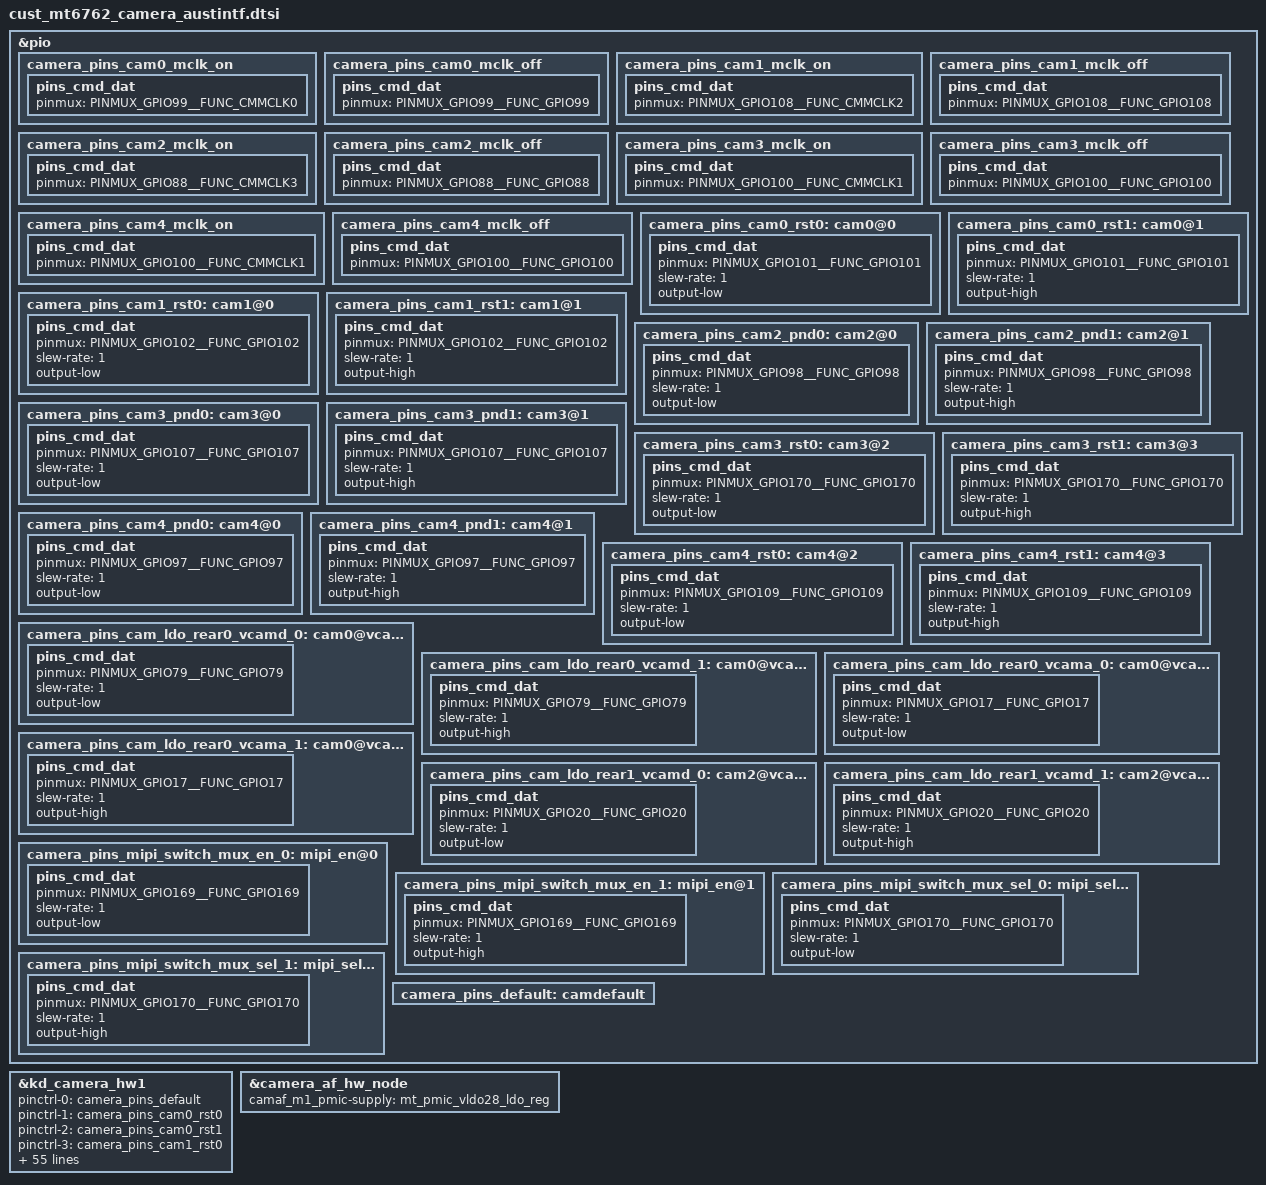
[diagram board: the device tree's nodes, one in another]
/* CAMERA GPIO standardization */
&pio {
/*clk*/
	camera_pins_cam0_mclk_on: camera_pins_cam0_mclk_on {
		pins_cmd_dat {
			pinmux = <PINMUX_GPIO99__FUNC_CMMCLK0>;
		};
	};
	camera_pins_cam0_mclk_off: camera_pins_cam0_mclk_off {
		pins_cmd_dat {
			pinmux = <PINMUX_GPIO99__FUNC_GPIO99>;
		};
	};
	camera_pins_cam1_mclk_on: camera_pins_cam1_mclk_on {
		pins_cmd_dat {
			pinmux = <PINMUX_GPIO108__FUNC_CMMCLK2>;
		};
	};
	camera_pins_cam1_mclk_off: camera_pins_cam1_mclk_off {
		pins_cmd_dat {
			pinmux = <PINMUX_GPIO108__FUNC_GPIO108>;
		};
	};
	camera_pins_cam2_mclk_on: camera_pins_cam2_mclk_on {
		pins_cmd_dat {
			pinmux = <PINMUX_GPIO88__FUNC_CMMCLK3>;
		};
	};
	camera_pins_cam2_mclk_off: camera_pins_cam2_mclk_off {
		pins_cmd_dat {
			pinmux = <PINMUX_GPIO88__FUNC_GPIO88>;
		};
	};
	camera_pins_cam3_mclk_on: camera_pins_cam3_mclk_on {
		pins_cmd_dat {
			pinmux = <PINMUX_GPIO100__FUNC_CMMCLK1>;
		};
	};
	camera_pins_cam3_mclk_off: camera_pins_cam3_mclk_off {
		pins_cmd_dat {
			pinmux = <PINMUX_GPIO100__FUNC_GPIO100>;
		};
	};
	camera_pins_cam4_mclk_on: camera_pins_cam4_mclk_on {
		pins_cmd_dat {
			pinmux = <PINMUX_GPIO100__FUNC_CMMCLK1>;
		};
	};
	camera_pins_cam4_mclk_off: camera_pins_cam4_mclk_off {
		pins_cmd_dat {
			pinmux = <PINMUX_GPIO100__FUNC_GPIO100>;
		};
	};

/*rst/pnd*/
	camera_pins_cam0_rst0: cam0@0 {
		pins_cmd_dat {
			pinmux = <PINMUX_GPIO101__FUNC_GPIO101>;
			slew-rate = <1>;
			output-low;
		};
	};
	camera_pins_cam0_rst1: cam0@1 {
		pins_cmd_dat {
			pinmux = <PINMUX_GPIO101__FUNC_GPIO101>;
			slew-rate = <1>;
			output-high;
		};
	};

	camera_pins_cam1_rst0: cam1@0 {
		pins_cmd_dat {
			pinmux = <PINMUX_GPIO102__FUNC_GPIO102>;
			slew-rate = <1>;
			output-low;
		};
	};
	camera_pins_cam1_rst1: cam1@1 {
		pins_cmd_dat {
			pinmux = <PINMUX_GPIO102__FUNC_GPIO102>;
			slew-rate = <1>;
			output-high;
		};
	};

	camera_pins_cam2_pnd0: cam2@0 {
		pins_cmd_dat {
			pinmux = <PINMUX_GPIO98__FUNC_GPIO98>;
			slew-rate = <1>;
			output-low;
		};
	};
	camera_pins_cam2_pnd1: cam2@1 {
		pins_cmd_dat {
			pinmux = <PINMUX_GPIO98__FUNC_GPIO98>;
			slew-rate = <1>;
			output-high;
		};
	};

	camera_pins_cam3_pnd0: cam3@0 {
		pins_cmd_dat {
			pinmux = <PINMUX_GPIO107__FUNC_GPIO107>;
			slew-rate = <1>;
			output-low;
		};
	};
	camera_pins_cam3_pnd1: cam3@1 {
		pins_cmd_dat {
			pinmux = <PINMUX_GPIO107__FUNC_GPIO107>;
			slew-rate = <1>;
			output-high;
		};
	};

	//mipi switch sel
	camera_pins_cam3_rst0: cam3@2 {
		pins_cmd_dat {
			pinmux = <PINMUX_GPIO170__FUNC_GPIO170>;
			slew-rate = <1>;
			output-low;
		};
	};
	camera_pins_cam3_rst1: cam3@3 {
		pins_cmd_dat {
			pinmux = <PINMUX_GPIO170__FUNC_GPIO170>;
			slew-rate = <1>;
			output-high;
		};
	};

	camera_pins_cam4_pnd0: cam4@0 {
		pins_cmd_dat {
			pinmux = <PINMUX_GPIO97__FUNC_GPIO97>;
			slew-rate = <1>;
			output-low;
		};
	};
	camera_pins_cam4_pnd1: cam4@1 {
		pins_cmd_dat {
			pinmux = <PINMUX_GPIO97__FUNC_GPIO97>;
			slew-rate = <1>;
			output-high;
		};
	};
	camera_pins_cam4_rst0: cam4@2 {
		pins_cmd_dat {
			pinmux = <PINMUX_GPIO109__FUNC_GPIO109>;
			slew-rate = <1>;
			output-low;
		};
	};
	camera_pins_cam4_rst1: cam4@3 {
		pins_cmd_dat {
			pinmux = <PINMUX_GPIO109__FUNC_GPIO109>;
			slew-rate = <1>;
			output-high;
		};
	};

/*avdd/dvdd LDO*/
	camera_pins_cam_ldo_rear0_vcamd_0: cam0@vcamd0 {
		pins_cmd_dat {
			pinmux = <PINMUX_GPIO79__FUNC_GPIO79>;
			slew-rate = <1>;
			output-low;
		};
	};
	camera_pins_cam_ldo_rear0_vcamd_1: cam0@vcamd1 {
		pins_cmd_dat {
			pinmux = <PINMUX_GPIO79__FUNC_GPIO79>;
			slew-rate = <1>;
			output-high;
		};
	};
	camera_pins_cam_ldo_rear0_vcama_0: cam0@vcama0 {
		pins_cmd_dat {
			pinmux = <PINMUX_GPIO17__FUNC_GPIO17>;
			slew-rate = <1>;
			output-low;
		};
	};
	camera_pins_cam_ldo_rear0_vcama_1: cam0@vcama1 {
		pins_cmd_dat {
			pinmux = <PINMUX_GPIO17__FUNC_GPIO17>;
			slew-rate = <1>;
			output-high;
		};
	};

	camera_pins_cam_ldo_rear1_vcamd_0: cam2@vcamd0 {
		pins_cmd_dat {
			pinmux = <PINMUX_GPIO20__FUNC_GPIO20>;
			slew-rate = <1>;
			output-low;
		};
	};
	camera_pins_cam_ldo_rear1_vcamd_1: cam2@vcamd1 {
		pins_cmd_dat {
			pinmux = <PINMUX_GPIO20__FUNC_GPIO20>;
			slew-rate = <1>;
			output-high;
		};
	};

	camera_pins_mipi_switch_mux_en_0: mipi_en@0 {
		pins_cmd_dat {
			pinmux = <PINMUX_GPIO169__FUNC_GPIO169>;
			slew-rate = <1>;
			output-low;
		};
	};
	camera_pins_mipi_switch_mux_en_1: mipi_en@1 {
		pins_cmd_dat {
			pinmux = <PINMUX_GPIO169__FUNC_GPIO169>;
			slew-rate = <1>;
			output-high;
		};
	};

	camera_pins_mipi_switch_mux_sel_0: mipi_sel@0 {
		pins_cmd_dat {
			pinmux = <PINMUX_GPIO170__FUNC_GPIO170>;
			slew-rate = <1>;
			output-low;
		};
	};
	camera_pins_mipi_switch_mux_sel_1: mipi_sel@1 {
		pins_cmd_dat {
			pinmux = <PINMUX_GPIO170__FUNC_GPIO170>;
			slew-rate = <1>;
			output-high;
		};
	};


	camera_pins_default: camdefault {
	};

};

&kd_camera_hw1 {
	pinctrl-names = "default",
			"cam0_rst0",
			"cam0_rst1",

			"cam1_rst0",
			"cam1_rst1",

			"cam2_pnd0",
			"cam2_pnd1",

			"cam3_pnd0",
			"cam3_pnd1",

			//mipi switch sel
			"cam3_rst0",
			"cam3_rst1",

			"cam4_pnd0",
			"cam4_pnd1",
			"cam4_rst0",
			"cam4_rst1",

			"cam0_vcamd_on",
			"cam0_vcamd_off",
			"cam0_vcama_on",
			"cam0_vcama_off",

			"cam1_vcama_on",
			"cam1_vcama_off",

			"cam2_vcamd_on",
			"cam2_vcamd_off",

			"cam3_vcamd_on",
			"cam3_vcamd_off",
			"cam3_vcama_on",
			"cam3_vcama_off",

			"cam0_mclk_on",
			"cam0_mclk_off",
			"cam1_mclk_on",
			"cam1_mclk_off",
			"cam2_mclk_on",
			"cam2_mclk_off",
			"cam3_mclk_on",
			"cam3_mclk_off",
			"cam4_mclk_on",
			"cam4_mclk_off",

			"cam_mipi_switch_en_1",
			"cam_mipi_switch_en_0",
			"cam_mipi_switch_sel_1",
			"cam_mipi_switch_sel_0";

	pinctrl-0 = <&camera_pins_default>;
	pinctrl-1 = <&camera_pins_cam0_rst0>;
	pinctrl-2 = <&camera_pins_cam0_rst1>;

	pinctrl-3 = <&camera_pins_cam1_rst0>;
	pinctrl-4 = <&camera_pins_cam1_rst1>;

	pinctrl-5 = <&camera_pins_cam2_pnd0>;
	pinctrl-6 = <&camera_pins_cam2_pnd1>;

	pinctrl-7 = <&camera_pins_cam3_pnd0>;
	pinctrl-8 = <&camera_pins_cam3_pnd1>;

	//mipi switch sel
	pinctrl-9 = <&camera_pins_cam3_rst0>;
	pinctrl-10 = <&camera_pins_cam3_rst1>;

	pinctrl-11 = <&camera_pins_cam4_pnd0>;
	pinctrl-12 = <&camera_pins_cam4_pnd1>;
	pinctrl-13 = <&camera_pins_cam4_rst0>;
	pinctrl-14 = <&camera_pins_cam4_rst1>;

	pinctrl-15 = <&camera_pins_cam_ldo_rear0_vcamd_1>;
	pinctrl-16 = <&camera_pins_cam_ldo_rear0_vcamd_0>;
	pinctrl-17 = <&camera_pins_cam_ldo_rear0_vcama_1>;
	pinctrl-18 = <&camera_pins_cam_ldo_rear0_vcama_0>;

	pinctrl-19 = <&camera_pins_cam_ldo_rear0_vcama_1>;
	pinctrl-20 = <&camera_pins_cam_ldo_rear0_vcama_0>;

	pinctrl-21 = <&camera_pins_cam_ldo_rear1_vcamd_1>;
	pinctrl-22 = <&camera_pins_cam_ldo_rear1_vcamd_0>;

	pinctrl-23 = <&camera_pins_cam_ldo_rear1_vcamd_1>;
	pinctrl-24 = <&camera_pins_cam_ldo_rear1_vcamd_0>;
	pinctrl-25 = <&camera_pins_cam_ldo_rear0_vcama_1>;
	pinctrl-26 = <&camera_pins_cam_ldo_rear0_vcama_0>;

	pinctrl-27 = <&camera_pins_cam0_mclk_on>;
	pinctrl-28 = <&camera_pins_cam0_mclk_off>;
	pinctrl-29 = <&camera_pins_cam1_mclk_on>;
	pinctrl-30 = <&camera_pins_cam1_mclk_off>;
	pinctrl-31 = <&camera_pins_cam2_mclk_on>;
	pinctrl-32 = <&camera_pins_cam2_mclk_off>;
	pinctrl-33 = <&camera_pins_cam3_mclk_on>;
	pinctrl-34 = <&camera_pins_cam3_mclk_off>;
	pinctrl-35 = <&camera_pins_cam4_mclk_on>;
	pinctrl-36 = <&camera_pins_cam4_mclk_off>;

	pinctrl-37 = <&camera_pins_mipi_switch_mux_en_1>;
	pinctrl-38 = <&camera_pins_mipi_switch_mux_en_0>;
	pinctrl-39 = <&camera_pins_mipi_switch_mux_sel_1>;
	pinctrl-40 = <&camera_pins_mipi_switch_mux_sel_0>;

	cam0_vcamio-supply = <&mt_pmic_vcamio_ldo_reg>;

	cam1_vcamio-supply = <&mt_pmic_vcamio_ldo_reg>;
	cam1_vcamd-supply = <&mt_pmic_vcamd_ldo_reg>;

	cam2_vcamio-supply = <&mt_pmic_vcamio_ldo_reg>;
	cam2_vcama-supply = <&mt_pmic_vcama_ldo_reg>;

	cam3_vcamio-supply = <&mt_pmic_vcamio_ldo_reg>;

	cam4_vcamio-supply = <&mt_pmic_vcamio_ldo_reg>;
	cam4_vcama-supply = <&mt_pmic_vcama_ldo_reg>;
	cam4_vcamd-supply = <&mt_pmic_vcamd_ldo_reg>;

	cam0_vldo28-supply = <&mt_pmic_vldo28_ldo_reg>;

	cam0_enable_sensor = "tsppsnp1269_s5kjn1_mipi_raw";
	cam1_enable_sensor = "tspscf0002_s5k3l6_mipi_raw shnbmd28b_ov13b10_mipi_raw";
	cam2_enable_sensor = "cxtvc12499_gc02m1b_mipi_raw";
	cam3_enable_sensor = "shnbf204c_gc02m1_mipi_raw";
	cam4_enable_sensor = "shnaf538m_gc5035_mipi_raw";

	status = "okay";

};

&camera_af_hw_node {
       camaf_m1_pmic-supply = <&mt_pmic_vldo28_ldo_reg>;
       status = "okay";
};

/* CAMERA GPIO end */
